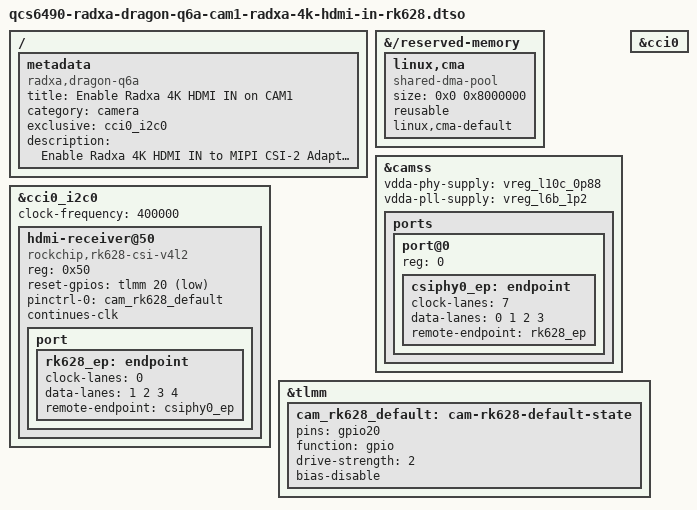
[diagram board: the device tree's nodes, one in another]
// SPDX-License-Identifier: BSD-3-Clause
/*
 * Copyright (c) 2026 Radxa Computer (Shenzhen) Co., Ltd.
 */

/dts-v1/;
/plugin/;

#include <dt-bindings/clock/qcom,camcc-sc7280.h>
#include <dt-bindings/gpio/gpio.h>

/ {
	metadata {
		title = "Enable Radxa 4K HDMI IN on CAM1";
		compatible = "radxa,dragon-q6a";
		category = "camera";
		exclusive = "cci0_i2c0";
		description = "Enable Radxa 4K HDMI IN to MIPI CSI-2 Adapter (RK628) on CAM1.";
	};
};

&{/reserved-memory} {
	linux,cma {
		compatible = "shared-dma-pool";
		size = <0x0 0x8000000>;
		reusable;
		linux,cma-default;
	};
};

&camss {
	vdda-phy-supply = <&vreg_l10c_0p88>;
	vdda-pll-supply = <&vreg_l6b_1p2>;

	status = "okay";

	ports {
		#address-cells = <1>;
		#size-cells = <0>;

		/* CAM1 is connected to CSIPHY0. */
		port@0 {
			reg = <0>;

			csiphy0_ep: endpoint {
				clock-lanes = <7>;
				data-lanes = <0 1 2 3>;
				remote-endpoint = <&rk628_ep>;
			};
		};
	};
};

&cci0 {
	status = "okay";
};

&cci0_i2c0 {
	#address-cells = <1>;
	#size-cells = <0>;
	clock-frequency = <400000>;

	hdmi-receiver@50 {
		compatible = "rockchip,rk628-csi-v4l2";
		reg = <0x50>;

		reset-gpios = <&tlmm 20 GPIO_ACTIVE_LOW>;
		pinctrl-0 = <&cam_rk628_default>;
		pinctrl-names = "default";

		/* No interrupt wiring: use the driver's polling mode. */
		continues-clk;

		port {
			rk628_ep: endpoint {
				clock-lanes = <0>;
				data-lanes = <1 2 3 4>;
				remote-endpoint = <&csiphy0_ep>;
			};
		};
	};
};

&tlmm {
	cam_rk628_default: cam-rk628-default-state {
		pins = "gpio20";
		function = "gpio";
		drive-strength = <2>;
		bias-disable;
	};
};
